# KM1M7CF16 register map
Vendor: Nuvoton Technology Corporation Japan; Series: KM1M7CF; File version: 1.0.3
CPU: CM7 r1p2, little endian, MPU, FPU, double-precision FPU, I-cache, D-cache, ITCM, DTCM, 4 interrupt priority bits
Registers are 32-bit, read-write, no defined reset value unless marked. A register's access mark holds for its fields unless they carry their own. Offsets are from the block's base; [hi:lo] are bit positions; {n}, {i} and the like mark numbered series.

## CAN — CAN FD Cotroller
Base 0x40110000
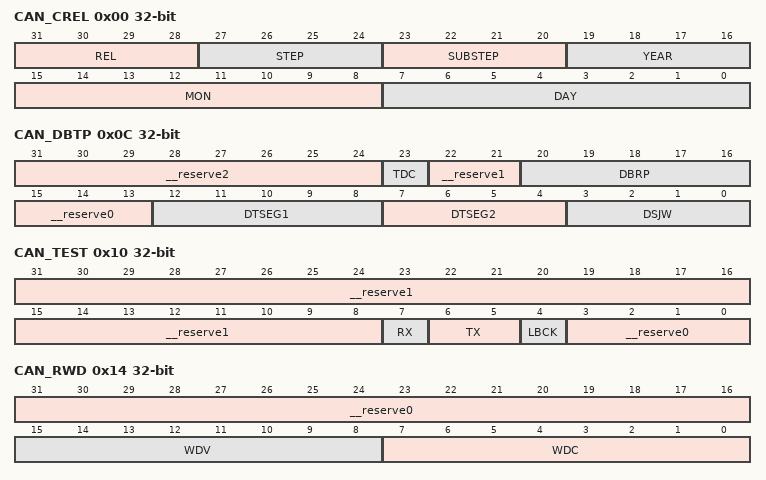
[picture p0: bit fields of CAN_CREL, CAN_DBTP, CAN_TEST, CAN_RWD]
0x00 CAN_CREL ro — CAN Core Release Register
  [31:28] REL — Core Release Version
  [27:24] STEP — Step of Core Release
  [23:20] SUBSTEP — Sub-step of Core Release
  [19:16] YEAR — Time Stamp Year
  [15:8] MON — Time Stamp Month
  [7:0] DAY — Time Stamp Day
0x0C CAN_DBTP access per field — CAN Data Bit Timing & Prescaler Register
  [31:24] __reserve2 ro — "0" is always read out.
  [23] TDC rw — Transmitter Delay Compensation
  [22:21] __reserve1 ro — "0" is always read out.
  [20:16] DBRP rw — Data Bit Rate Prescaler
  [15:13] __reserve0 ro — "0" is always read out.
  [12:8] DTSEG1 rw — Data time segment before sample point
  [7:4] DTSEG2 rw — Data time segment after sample point
  [3:0] DSJW rw — Data (Re)Synchronization Jump Width
0x10 CAN_TEST access per field
  [31:8] __reserve1 ro — "0" is always read out.
  [7] RX ro — Monitors the actual value of CRX pin
  [6:5] TX rw — Control of Transmit Pin CTX (*1)
  [4] LBCK rw — Loop Back Mode
  [3:0] __reserve0 ro — "0" is always read out.
0x14 CAN_RWD access per field — CAN RAM Watchdog Register
  [31:16] __reserve0 ro — "0" is always read out.
  [15:8] WDV ro — Watchdog Value
  [7:0] WDC rw — Watchdog Configuration
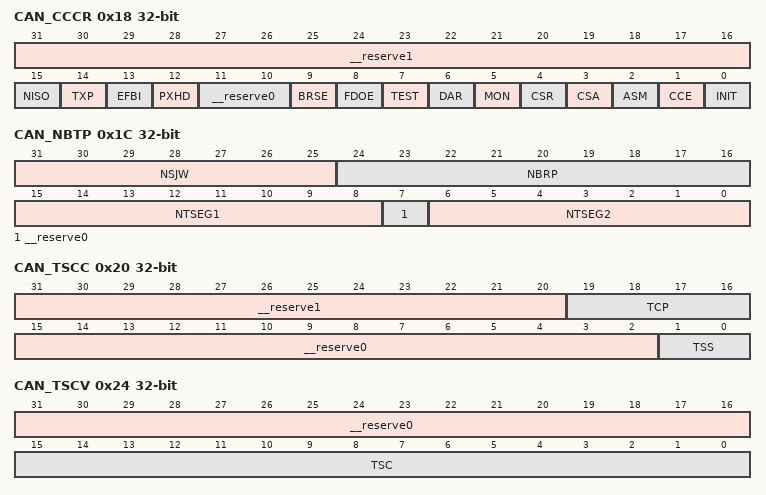
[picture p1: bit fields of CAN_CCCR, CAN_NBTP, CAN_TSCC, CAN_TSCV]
0x18 CAN_CCCR access per field — CAN CC Control Register
  [31:16] __reserve1 ro — "0" is always read out.
  [15] NISO rw — Non ISO Operation (*1)
  [14] TXP rw — Transmit Pause
  [13] EFBI rw — Edge Filtering during Bus Integration (*1)
  [12] PXHD rw — Protocol Exception Handling Disable (*1)
  [11:10] __reserve0 ro — "0" is always read out.
  [9] BRSE rw — Bit Rate Switch Enable (*1)
  [8] FDOE rw — CAN FD Operation Enable (*1)
  [7] TEST rw — Test Mode Enable (*2)
  [6] DAR rw — Disable Automatic Retransmission (*1)
  [5] MON rw — Bus Monitoring Mode (*2)
  [4] CSR rw — Clock Stop Request (*3)
  [3] CSA ro — Clock Stop Acknowledge
  [2] ASM rw — Restricted Operation Mode (*2)
  [1] CCE rw — Configuration Change Enable (*1) (*4)
  [0] INIT rw — Initialization (*5)
0x1C CAN_NBTP access per field — CAN Nominal Bit Timing & Prescaler Register
  [31:25] NSJW rw — Nominal (Re)Synchronization Jump Width
  [24:16] NBRP rw — Nominal Bit Rate Prescaler
  [15:8] NTSEG1 rw — Nominal Time segment (TSEG1) before sample point
  [7] __reserve0 ro — "0" is always read out.
  [6:0] NTSEG2 rw — Nominal Time segment (TSEG2) after sample point
0x20 CAN_TSCC access per field — CAN Timestamp Counter Configuration Register
  [31:20] __reserve1 ro — "0" is always read out.
  [19:16] TCP rw — Timestamp Counter Prescaler
  [15:2] __reserve0 ro — "0" is always read out.
  [1:0] TSS rw — Timestamp Selection
0x24 CAN_TSCV access per field — CAN Timestamp Counter Value Register
  [31:16] __reserve0 ro — "0" is always read out.
  [15:0] TSC rw — Timestamp Counter
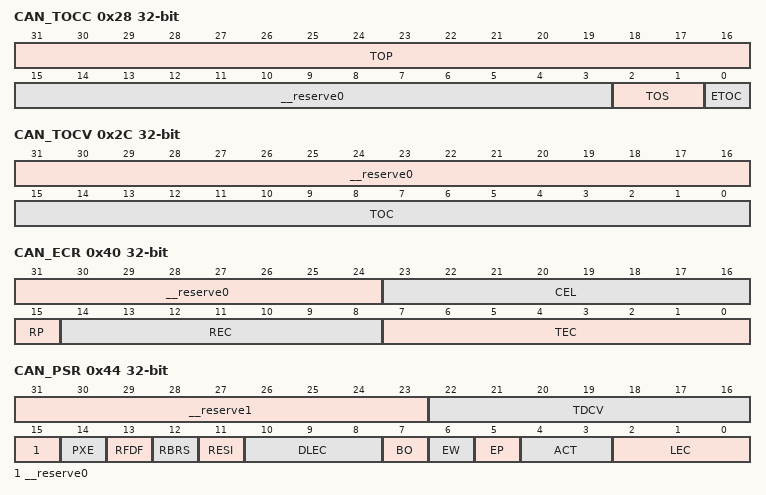
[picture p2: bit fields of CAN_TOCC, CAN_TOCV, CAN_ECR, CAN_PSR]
0x28 CAN_TOCC access per field — CAN Timeout Counter Configuration Register
  [31:16] TOP rw — Start value of the Timeout Counter (down-counter). Configures the Timeout Period.
  [15:3] __reserve0 ro — "0" is always read out.
  [2:1] TOS rw — Timeout Counter Operation mode Selection
  [0] ETOC rw — Enable Timeout Counter
0x2C CAN_TOCV access per field — CAN Timeout Counter Value Register
  [31:16] __reserve0 ro — "0" is always read out.
  [15:0] TOC rw — Timeout Counter Value
0x40 CAN_ECR ro — CAN Error Counter Register
  [31:24] __reserve0 — "0" is always read out.
  [23:16] CEL — CAN Error Logging (*1)
  [15] RP — Receive Error Passive
  [14:8] REC — Receive Error Counter
  [7:0] TEC — Transmit Error Counter
0x44 CAN_PSR ro — CAN Protocol Status Register
  [31:23] __reserve1 — "0" is always read out.
  [22:16] TDCV — Transmitter Delay Compensation Value (Position of the secondary sample point)
  [15] __reserve0 — "0" is always read out.
  [14] PXE — Protocol Exception Event (*1)
  [13] RFDF — Received a CAN FD Message (*1)
  [12] RBRS — BRS flag of last received CAN FD Message (*1)
  [11] RESI — ESI flag of last received CAN FD Message (*1)
  [10:8] DLEC — Data Phase Last Error Code
  [7] BO — Bus_Off Status
  [6] EW — Warning Status
  [5] EP — CAN Error Passive
  [4:3] ACT — Activity
  [2:0] LEC — Last error code to occur on the CAN bus.(*4) (*5)
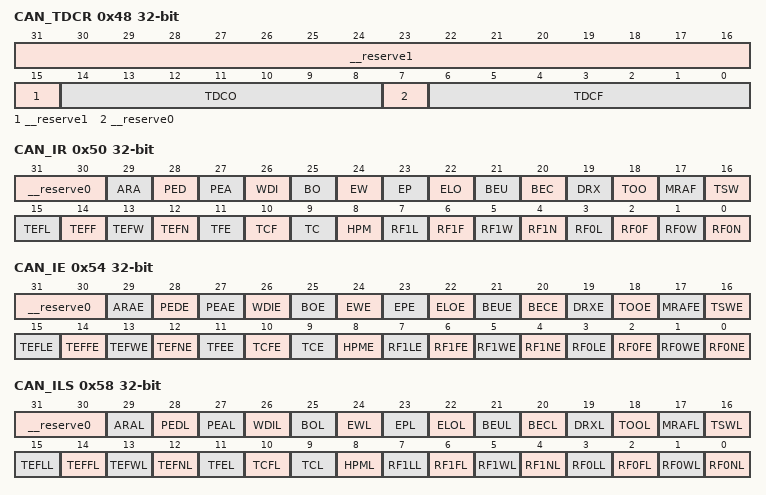
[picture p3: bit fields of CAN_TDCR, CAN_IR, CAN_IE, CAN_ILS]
0x48 CAN_TDCR access per field — CAN Transmitter Delay Compensation Register
  [31:15] __reserve1 ro — "0" is always read out.
  [14:8] TDCO rw — Transmitter Delay Compensation Offset
  [7] __reserve0 ro — "0" is always read out.
  [6:0] TDCF rw — Transmitter Delay Compensation Filter Window Length (*1)
0x50 CAN_IR access per field — CAN Interrupt Factor Register
  [31:30] __reserve0 ro — "0" is always read out.
  [29] ARA rw — Access to Reserved Address Interrupt Factor
  [28] PED rw — Protocol Error in Data Phase Interrupt Factor (Data Bit Time is used)
  [27] PEA rw — Protocol Error in Arbitration Phase Interrupt Factor (Nominal Bit Time is used)
  [26] WDI rw — Watchdog Interrupt Factor
  [25] BO rw — Bus_Off Status Interrupt Factor
  [24] EW rw — Warning Status Interrupt Factor
  [23] EP rw — Error Passive Interrupt Factor
  [22] ELO rw — Error Logging Overflow Interrupt Factor
  [21] BEU rw — Bit Error Uncorrected Interrupt Factor
  [20] BEC rw — Bit Error Corrected Interrupt Factor
  [19] DRX rw — Message stored to Dedicated Rx Buffer Interrupt Factor
  [18] TOO rw — Timeout Occurred Interrupt Factor
  [17] MRAF rw — Message RAM Access Failure Interrupt Factor
  [16] TSW rw — Timestamp Wraparound Interrupt Factor
  [15] TEFL rw — Tx Event FIFO Element Lost Interrupt Factor
  [14] TEFF rw — Tx Event FIFO Full Interrupt Factor
  [13] TEFW rw — Tx Event FIFO Watermark Reached Interrupt Factor
  [12] TEFN rw — Tx Event FIFO New Entry Interrupt Factor
  [11] TFE rw — Tx FIFO Empty Interrupt Factor
  [10] TCF rw — Transmission Cancellation Finished Interrupt Factor
  [9] TC rw — Transmission Completed Interrupt Factor
  [8] HPM rw — High Priority Message Interrupt Factor
  [7] RF1L rw — Rx FIFO 1 Message Lost Interrupt Factor
  [6] RF1F rw — Rx FIFO 1 Full Interrupt Factor
  [5] RF1W rw — Rx FIFO 1 Watermark Reached Interrupt Factor
  [4] RF1N rw — Rx FIFO 1 New Message Interrupt Factor
  [3] RF0L rw — Rx FIFO 0 Message Lost Interrupt Factor
  [2] RF0F rw — Rx FIFO 0 Full Interrupt Factor
  [1] RF0W rw — Rx FIFO 0 Watermark Reached Interrupt Factor
  [0] RF0N rw — Rx FIFO 0 New Message Interrupt Factor
0x54 CAN_IE access per field — CAN Interrupt Factor Enable Register
  [31:30] __reserve0 ro — "0" is always read out.
  [29] ARAE rw — Access to Reserved Address Interrupt Factor Enable
  [28] PEDE rw — Protocol Error in Data Phase Interrupt Factor Enable
  [27] PEAE rw — Protocol Error in Arbitration Phase Interrupt Factor Enable
  [26] WDIE rw — Watchdog Interrupt Factor Enable
  [25] BOE rw — Bus_Off Status Interrupt Factor Enable
  [24] EWE rw — Warning Status Interrupt Factor Enable
  [23] EPE rw — Error Passive Interrupt Factor Enable
  [22] ELOE rw — Error Logging Overflow Interrupt Factor Enable
  [21] BEUE rw — Bit Error Uncorrected Interrupt Factor Enable
  [20] BECE rw — Bit Error Corrected Interrupt Factor Enable
  [19] DRXE rw — Message stored to Dedicated Rx Buffer Interrupt Factor Enable
  [18] TOOE rw — Timeout Occurred Interrupt Factor Enable
  [17] MRAFE rw — Message RAM Access Failure Interrupt Factor Enable
  [16] TSWE rw — Timestamp Wraparound Interrupt Factor Enable
  [15] TEFLE rw — Tx Event FIFO Event Lost Interrupt Factor Enable
  [14] TEFFE rw — Tx Event FIFO Full Interrupt Factor Enable
  [13] TEFWE rw — Tx Event FIFO Watermark Reached Interrupt Factor Enable
  [12] TEFNE rw — Tx Event FIFO New Entry Interrupt Factor Enable
  [11] TFEE rw — Tx FIFO Empty Interrupt Factor Enable
  [10] TCFE rw — Transmission Cancellation Finished Interrupt Factor Enable
  [9] TCE rw — Transmission Completed Interrupt Factor Enable
  [8] HPME rw — High Priority Message Interrupt Factor Enable
  [7] RF1LE rw — Rx FIFO 1 Message Lost Interrupt Factor Enable
  [6] RF1FE rw — Rx FIFO 1 Full Interrupt Factor Enable
  [5] RF1WE rw — Rx FIFO 1 Watermark Reached Interrupt Factor Enable
  [4] RF1NE rw — Rx FIFO 1 New Message Interrupt Factor Enable
  [3] RF0LE rw — Rx FIFO 0 Message Lost Interrupt Factor Enable
  [2] RF0FE rw — Rx FIFO 0 Full Interrupt Factor Enable
  [1] RF0WE rw — Rx FIFO 0 Watermark Reached Interrupt Factor Enable
  [0] RF0NE rw — Rx FIFO 0 New Message Interrupt Factor Enable
0x58 CAN_ILS access per field — CAN Interrupt Line Select Register
  [31:30] __reserve0 ro — "0" is always read out.
  [29] ARAL rw — Access to Reserved Address Line
  [28] PEDL rw — Protocol Error in Data Phase Line
  [27] PEAL rw — Protocol Error in Arbitration Phase Line
  [26] WDIL rw — Watchdog Interrupt Line
  [25] BOL rw — Bus_Off Status Interrupt Line
  [24] EWL rw — Warning Status Interrupt Line
  [23] EPL rw — Error Passive Interrupt Line
  [22] ELOL rw — Error Logging Overflow Interrupt Line
  [21] BEUL rw — Bit Error Uncorrected Interrupt Line
  [20] BECL rw — Bit Error Corrected Interrupt Line
  [19] DRXL rw — Message stored to Dedicated Rx Buffer Interrupt Line
  [18] TOOL rw — Timeout Occurred Interrupt Line
  [17] MRAFL rw — Message RAM Access Failure Interrupt Line
  [16] TSWL rw — Timestamp Wraparound Interrupt Line
  [15] TEFLL rw — Tx Event FIFO Event Lost Interrupt Line
  [14] TEFFL rw — Tx Event FIFO Full Interrupt Line
  [13] TEFWL rw — Tx Event FIFO Watermark Reached Interrupt Line
  [12] TEFNL rw — Tx Event FIFO New Entry Interrupt Line
  [11] TFEL rw — Tx FIFO Empty Interrupt Line
  [10] TCFL rw — Transmission Cancellation Finished Interrupt Line
  [9] TCL rw — Transmission Completed Interrupt Line
  [8] HPML rw — High Priority Message Interrupt Line
  [7] RF1LL rw — Rx FIFO 1 Message Lost Interrupt Line
  [6] RF1FL rw — Rx FIFO 1 Full Interrupt Line
  [5] RF1WL rw — Rx FIFO 1 Watermark Reached Interrupt Line
  [4] RF1NL rw — Rx FIFO 1 New Message Interrupt Line
  [3] RF0LL rw — Rx FIFO 0 Message Lost Interrupt Line
  [2] RF0FL rw — Rx FIFO 0 Full Interrupt Line
  [1] RF0WL rw — Rx FIFO 0 Watermark Reached Interrupt Line
  [0] RF0NL rw — Rx FIFO 0 New Message Interrupt Line
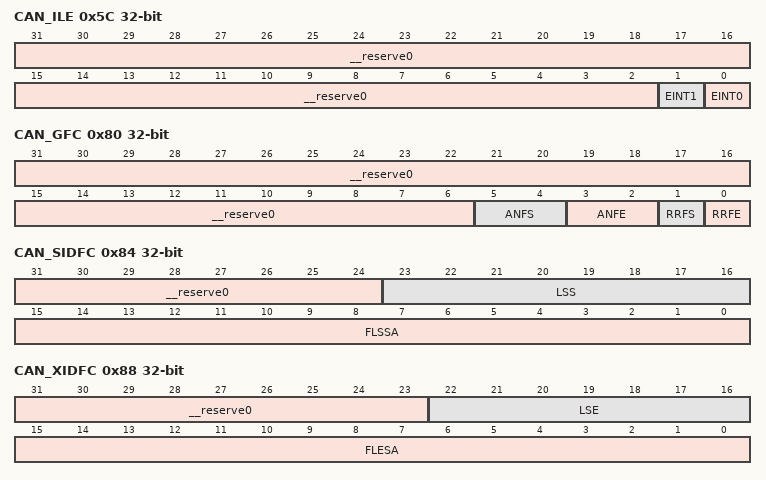
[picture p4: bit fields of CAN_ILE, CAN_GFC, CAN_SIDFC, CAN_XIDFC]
0x5C CAN_ILE access per field — CAN Interrupt Line Enable Register
  [31:2] __reserve0 ro — "0" is always read out.
  [1] EINT1 rw — Enable CAN-1 Interrupt
  [0] EINT0 rw — Enable CAN-0 Interrupt
0x80 CAN_GFC access per field — CAN Global Filter Configuration Register
  [31:6] __reserve0 ro — "0" is always read out.
  [5:4] ANFS rw — Accept Non-matching Frames Standard Message ID (11-bit)
  [3:2] ANFE rw — Accept Non-matching Frames Extended Message ID (29-bit)
  [1] RRFS rw — Reject Remote Frames Standard Message ID (11-bit)
  [0] RRFE rw — Reject Remote Frames Extended Message ID (29-bit)
0x84 CAN_SIDFC access per field — CAN Standard ID Filter Configuration Register
  [31:24] __reserve0 ro — "0" is always read out.
  [23:16] LSS rw — List Size Standard Message ID (11-bit)
  [15:0] FLSSA rw — Start address of Standard Message ID (11-bit) filter list (*1)
0x88 CAN_XIDFC access per field — CAN Extended ID Filter Configuration Register
  [31:23] __reserve0 ro — "0" is always read out.
  [22:16] LSE rw — List Size Extended Message ID (29-bit)
  [15:0] FLESA rw — Start address of Extended Message ID (29-bit) filter list (*1)
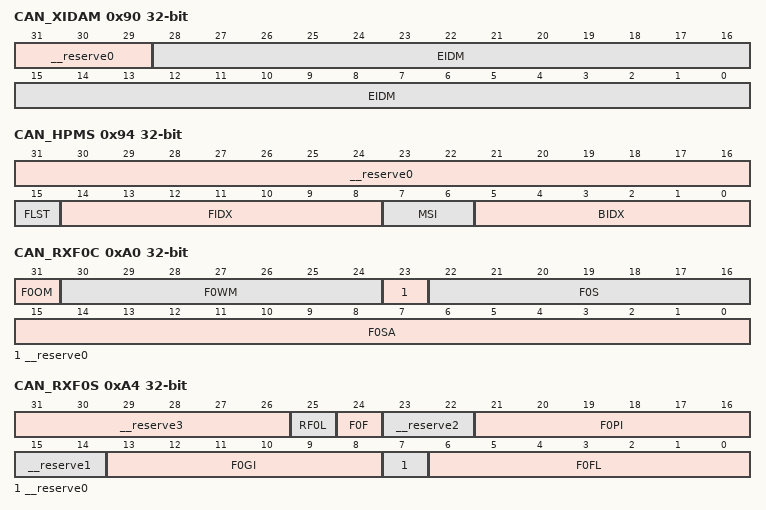
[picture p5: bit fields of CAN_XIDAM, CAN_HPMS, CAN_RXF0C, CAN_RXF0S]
0x90 CAN_XIDAM access per field — CAN Extended ID AND Mask Register
  [31:29] __reserve0 ro — "0" is always read out.
  [28:0] EIDM rw — Extended Message ID Mask (*1)
0x94 CAN_HPMS ro — CAN High Priority Message Status Register
  [31:16] __reserve0 — "0" is always read out.
  [15] FLST — Filter List
  [14:8] FIDX — Filter Index
  [7:6] MSI — Message Storage Indicator
  [5:0] BIDX — Buffer Index
0x98 CAN_NDAT1 — CAN New Data 1 Register
  [31:0] ND1 — New Data flags of Rx Buffers 0 to 31 (bp0 to 31)
0x9C CAN_NDAT2 — CAN New Data 2 Register
  [31:0] ND2 — New Data flags of Rx Buffers 32 to 63 (bp0 to 31)
0xA0 CAN_RXF0C access per field — CAN Rx FIFO 0 Configuration Register
  [31] F0OM rw — FIFO 0 Operation Mode
  [30:24] F0WM rw — Rx FIFO 0 Watermark
  [23] __reserve0 ro — "0" is always read out.
  [22:16] F0S rw — Rx FIFO 0 Size
  [15:0] F0SA rw — Start address of Rx FIFO 0 in Message RAM (*1)
0xA4 CAN_RXF0S ro — CAN Rx FIFO 0 Status Register
  [31:26] __reserve3 — "0" is always read out.
  [25] RF0L — Rx FIFO 0 Message Lost (*1) (*2)
  [24] F0F — Rx FIFO 0 Full
  [23:22] __reserve2 — "0" is always read out.
  [21:16] F0PI — Rx FIFO 0 Put Index
  [15:14] __reserve1 — "0" is always read out.
  [13:8] F0GI — Rx FIFO 0 Get Index
  [7] __reserve0 — "0" is always read out.
  [6:0] F0FL — Rx FIFO 0 Fill Level
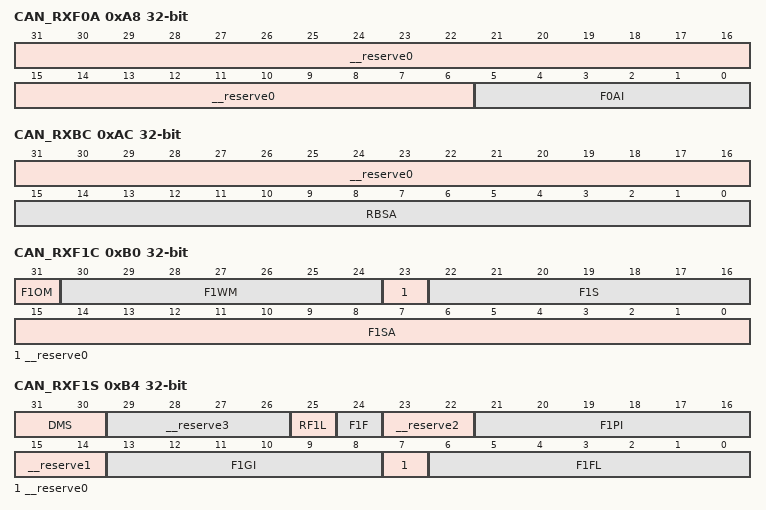
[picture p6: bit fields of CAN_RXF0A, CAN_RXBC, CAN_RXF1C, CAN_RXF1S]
0xA8 CAN_RXF0A access per field — CAN Rx FIFO 0 Acknowledge Register
  [31:6] __reserve0 ro — "0" is always read out.
  [5:0] F0AI rw — Rx FIFO 0 Acknowledge Index (*1)
0xAC CAN_RXBC access per field — CAN Rx Buffer Configuration Register
  [31:16] __reserve0 ro — "0" is always read out.
  [15:0] RBSA rw — Start address of Rx Buffers in Message RAM (*1) (*2)
0xB0 CAN_RXF1C access per field — CAN Rx FIFO 1 Configuration Register
  [31] F1OM rw — Rx FIFO 1 Operation Mode
  [30:24] F1WM rw — Rx FIFO 1 Watermark
  [23] __reserve0 ro — "0" is always read out.
  [22:16] F1S rw — Rx FIFO 1 Size
  [15:0] F1SA rw — Start address of Rx FIFO 1 in Message RAM (*1)
0xB4 CAN_RXF1S ro — CAN Rx FIFO 1 Status Register
  [31:30] DMS — Debug Message Status
  [29:26] __reserve3 — "0" is always read out.
  [25] RF1L — Rx FIFO 1 Message Lost (*1) (*2)
  [24] F1F — Rx FIFO 1 Full
  [23:22] __reserve2 — "0" is always read out.
  [21:16] F1PI — Rx FIFO 1 Put Index
  [15:14] __reserve1 — "0" is always read out.
  [13:8] F1GI — Rx FIFO 1 Get Index
  [7] __reserve0 — "0" is always read out.
  [6:0] F1FL — Rx FIFO 1 Fill Level
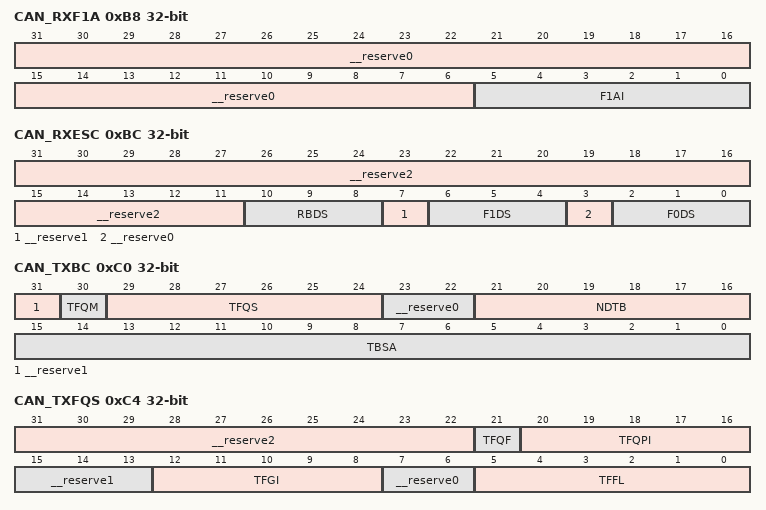
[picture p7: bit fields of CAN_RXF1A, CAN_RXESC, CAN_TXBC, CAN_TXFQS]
0xB8 CAN_RXF1A access per field — CAN Rx FIFO 1 Acknowledge Register
  [31:6] __reserve0 ro — "0" is always read out.
  [5:0] F1AI rw — Rx FIFO 1 Acknowledge Index
0xBC CAN_RXESC access per field — CAN Rx Buffer/ FIFO Element Size Configuration Register
  [31:11] __reserve2 ro — "0" is always read out.
  [10:8] RBDS rw — Rx Buffer Data Field Size (*1)
  [7] __reserve1 ro — "0" is always read out.
  [6:4] F1DS rw — Rx FIFO 1 Data Field Size (*1)
  [3] __reserve0 ro — "0" is always read out.
  [2:0] F0DS rw — Rx FIFO 0 Data Field Size (*1)
0xC0 CAN_TXBC access per field — CAN Tx Buffer Configuration Register
  [31] __reserve1 ro — "0" is always read out.
  [30] TFQM rw — Tx FIFO/Queue Mode
  [29:24] TFQS rw — Tx FIFO/Queue Size (*1)
  [23:22] __reserve0 ro — "0" is always read out.
  [21:16] NDTB rw — Number of Dedicated Tx Buffers (*1)
  [15:0] TBSA rw — Start address of Tx Buffers in Message RAM (*2) (*3)
0xC4 CAN_TXFQS ro — CAN Tx FIFO/Queue Status Register
  [31:22] __reserve2 — "0" is always read out.
  [21] TFQF — Tx FIFO/Queue Full
  [20:16] TFQPI — Tx FIFO/Queue Put Index
  [15:13] __reserve1 — "0" is always read out.
  [12:8] TFGI — Tx FIFO Get Index (*1)
  [7:6] __reserve0 — "0" is always read out.
  [5:0] TFFL — Tx FIFO Free Level
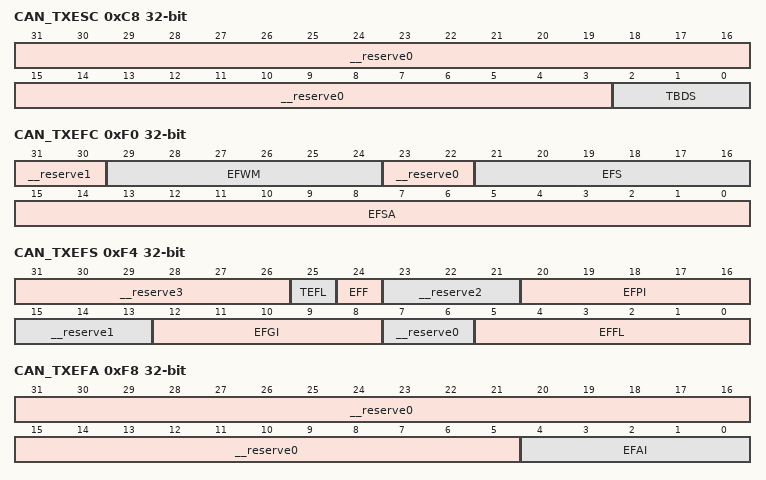
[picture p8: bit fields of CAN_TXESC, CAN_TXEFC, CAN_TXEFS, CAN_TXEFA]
0xC8 CAN_TXESC access per field — CAN Tx Buffer Element Size Configuration Register
  [31:3] __reserve0 ro — "0" is always read out.
  [2:0] TBDS rw — Tx Buffer Data Field Size (*1)
0xCC CAN_TXBRP ro — CAN Tx Buffer Request Pending Register
  [31:0] TRP — Transmission Request Pending
0xD0 CAN_TXBAR — CAN Tx Buffer Add Request Register
  [31:0] AR — Add Request
0xD4 CAN_TXBCR — CAN Tx Buffer Cancellation Request Register
  [31:0] CR — Cancellation Request
0xD8 CAN_TXBTO ro — CAN Tx Buffer Transmission Occurred Register
  [31:0] TO — Transmission Occurred
0xDC CAN_TXBCF ro — CAN Tx Buffer Cancellation Finished Register
  [31:0] CF — Transmit Buffer Cancellation Finished
0xE0 CAN_TXBTIE — CAN Tx Buffer Transmission Interrupt Enable Register
  [31:0] TIE — Tx Buffer Transmission Interrupt Enable
0xE4 CAN_TXBCIE — CAN Tx Buffer Cancellation Finished Interrupt Enable Register
  [31:0] CFIE — Tx Buffer Cancellation Finished Interrupt Enable
0xF0 CAN_TXEFC access per field — CAN Tx Event FIFO Configuration Register
  [31:30] __reserve1 ro — "0" is always read out.
  [29:24] EFWM rw — Event FIFO Watermark
  [23:22] __reserve0 ro — "0" is always read out.
  [21:16] EFS rw — Event FIFO Size
  [15:0] EFSA rw — Start address of Tx Event FIFO in Message RAM (*1)
0xF4 CAN_TXEFS ro — CAN Tx Event FIFO Status Register
  [31:26] __reserve3 — "0" is always read out.
  [25] TEFL — Tx Event FIFO Element Lost (*1)
  [24] EFF — Event FIFO Full
  [23:21] __reserve2 — "0" is always read out.
  [20:16] EFPI — Event FIFO Put Index
  [15:13] __reserve1 — "0" is always read out.
  [12:8] EFGI — Event FIFO Get Index
  [7:6] __reserve0 — "0" is always read out.
  [5:0] EFFL — Event FIFO Fill Level
0xF8 CAN_TXEFA access per field — CAN Tx Event FIFO Acknowledge Register
  [31:5] __reserve0 ro — "0" is always read out.
  [4:0] EFAI rw — Event FIFO Acknowledge Index
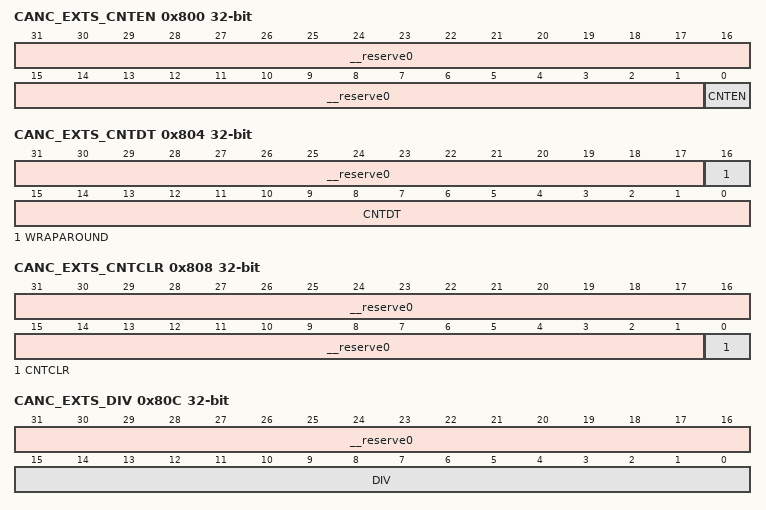
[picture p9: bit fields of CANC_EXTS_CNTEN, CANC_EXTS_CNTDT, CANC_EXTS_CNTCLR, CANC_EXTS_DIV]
0x800 CANC_EXTS_CNTEN access per field — External Timestamp Counter Control Register
  [31:1] __reserve0 ro — "0" is always read out.
  [0] CNTEN rw — Operation control of External timestamp counter
0x804 CANC_EXTS_CNTDT ro — External Timestamp Counter Display Register
  [31:17] __reserve0 — "0" is always read out.
  [16] WRAPAROUND — Status of External timestamp counter
  [15:0] CNTDT — Display the value of External timestamp counter.
0x808 CANC_EXTS_CNTCLR access per field — External Timestamp Counter Clear Register
  [31:1] __reserve0 ro — "0" is always read out.
  [0] CNTCLR wo — Clear the value of External timestamp counter (*1)
0x80C CANC_EXTS_DIV access per field — External Timestamp Counter Dividing Register
  [31:16] __reserve0 ro — "0" is always read out.
  [15:0] DIV rw — Clock dividing ratio of External timestamp counter (*1)
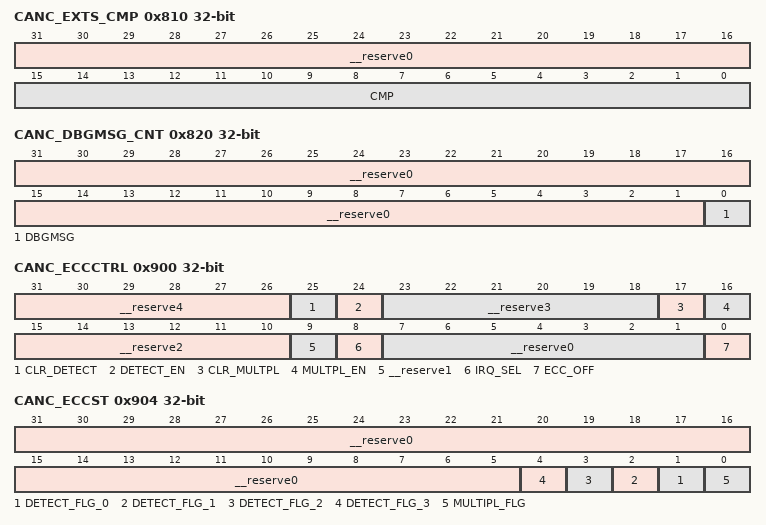
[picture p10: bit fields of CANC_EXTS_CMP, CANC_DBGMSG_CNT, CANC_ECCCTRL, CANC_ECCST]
0x810 CANC_EXTS_CMP access per field — External Timestamp Counter Compare Clear Register
  [31:16] __reserve0 ro — "0" is always read out.
  [15:0] CMP rw — Set the compare value of External timestamp counter.
0x820 CANC_DBGMSG_CNT access per field — Debug Message Control Register
  [31:1] __reserve0 ro — "0" is always read out.
  [0] DBGMSG rw — Debug Message Request of CAN
0x900 CANC_ECCCTRL access per field — ECC Function Setting Register
  [31:26] __reserve4 ro — "0" is always read out.
  [25] CLR_DETECT rw — Clear each status information detected when ECC error (1 bit or more) occurs (*1)
  [24] DETECT_EN rw — Enable each status information detection function when ECC error (1 bit or more) occurs
  [23:18] __reserve3 ro — "0" is always read out.
  [17] CLR_MULTPL rw — Clear each status information detected when ECC error (2 bits) occurs (*1)
  [16] MULTPL_EN rw — Enable each status information detection function when ECC error (2 bits) occurs
  [15:10] __reserve2 ro — "0" is always read out.
  [9] __reserve1 rw — This bit must be set to "0".
  [8] IRQ_SEL rw — Interrupt factor selection when ECC error occurs
  [7:1] __reserve0 ro — "0" is always read out.
  [0] ECC_OFF rw — ECC function ON/OFF
0x904 CANC_ECCST ro — ECC Error Detection Flag Register
  [31:5] __reserve0 — "0" is always read out.
  [n+1] DETECT_FLG_{n} (n=0..3) — ECC error (1 bit or more) occurrence (*1)
  [0] MULTIPL_FLG — ECC error (2 bits) occurrence detection (*2)
0x90C CANC_ECCRAM_DBG — ECCRAM Debug Register
  [31:0] ECCRAM_DBG_KEY — Switching access route to ECC part of message RAM
0x910 CANC_ERR_MULTPL_ADDR ro — ECC Error (2 bits) Detection Address Register
  [31:0] ERR_MULTPL_ADDR — Detect and display address at the time of ECC error (2 bits) occurrence.
0x914 CANC_ERR_MULTPL_DATA ro — ECC Error (2 bits) Detection Data Register
  [31:0] ERR_MULTPL_DATA — Detect and display data at the time of ECC error (2 bits) occurrence.
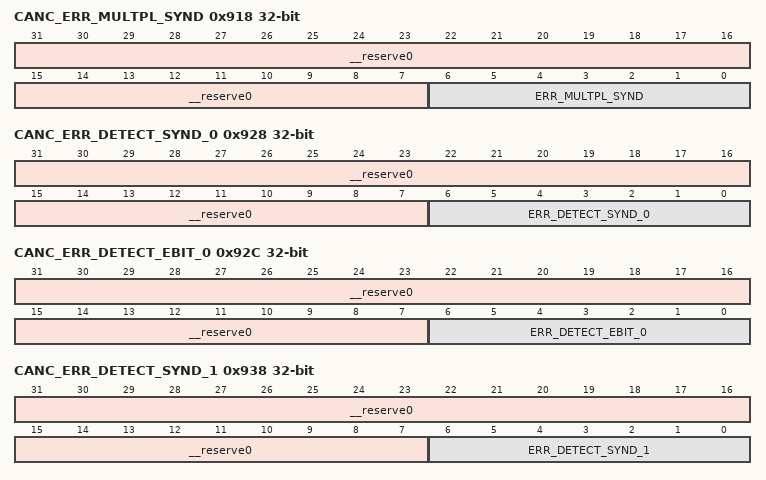
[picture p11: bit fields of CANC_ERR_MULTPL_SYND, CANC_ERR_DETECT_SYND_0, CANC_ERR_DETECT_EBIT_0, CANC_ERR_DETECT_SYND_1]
0x918 CANC_ERR_MULTPL_SYND ro — ECC Error (2 bits) Detection ECC Data Register
  [31:7] __reserve0 — "0" is always read out.
  [6:0] ERR_MULTPL_SYND — Detect and display ECC data at the time of ECC error (2 bits) occurrence.
{0x920+0x10*i} CANC_ERR_DETECT_ADDR_{i} ro (i=0..3) — ECC Error (1 bit or more) Detection Address Register {i}
  [31:0] ERR_DETECT_ADDR_{i} — Detect and display address at the time of ECC error (1 bit or more) occurrence.
0x924 CANC_ERR_DETECT_DATA_0 ro — ECC Error (1 bit or more) Detection Data Register 0
  [31:0] ERR_DETECT_DATA_0 — Detect data at the time of ECC error (1 bit or more) occurrence, and display the value before correction.
0x928 CANC_ERR_DETECT_SYND_0 ro — ECC Error (1 bit or more) Detection ECC Data Register 0
  [31:7] __reserve0 — "0" is always read out.
  [6:0] ERR_DETECT_SYND_0 — Detect ECC data at the time of ECC error (1 bit or more) occurrence, and display the value before correction.
0x92C CANC_ERR_DETECT_EBIT_0 ro — ECC Error (1 bit or more) Target Bit Register 0
  [31:7] __reserve0 — "0" is always read out.
  [6:0] ERR_DETECT_EBIT_0 — Detect and display the target bit at the time of ECC error (1 bit or more) occurrence.
0x934 CANC_ERR_DETECT_DATA_1 ro — ECC Error (1 bit or more) Detection Data Register 1
  [31:0] ERR_DETECT_DATA_1 — Detect data at the time of ECC error (1 bit or more) occurrence, and display the value before correction.
0x938 CANC_ERR_DETECT_SYND_1 ro — ECC Error (1 bit or more) Detection ECC Data Register 1
  [31:7] __reserve0 — "0" is always read out.
  [6:0] ERR_DETECT_SYND_1 — Detect ECC data at the time of ECC error (1 bit or more) occurrence, and display the value before correction.
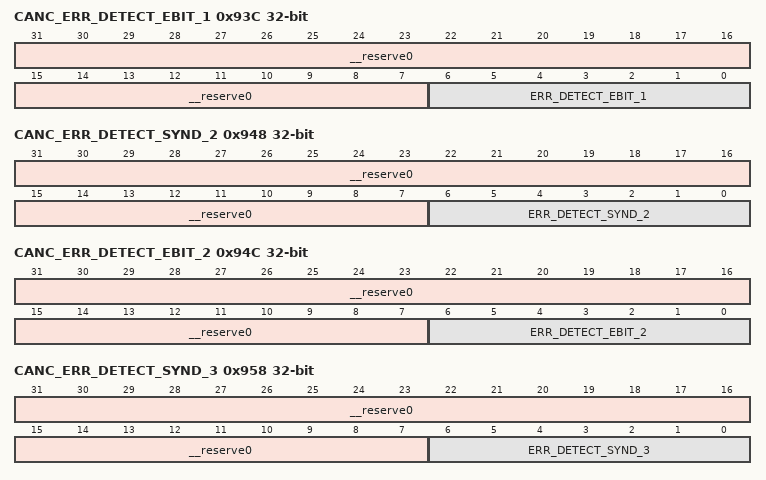
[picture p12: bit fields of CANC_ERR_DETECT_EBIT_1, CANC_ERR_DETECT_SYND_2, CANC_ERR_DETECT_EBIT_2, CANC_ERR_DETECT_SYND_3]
0x93C CANC_ERR_DETECT_EBIT_1 ro — ECC Error (1 bit or more) Target Bit Register 1
  [31:7] __reserve0 — "0" is always read out.
  [6:0] ERR_DETECT_EBIT_1 — Detect and display the target bit at the time of ECC error (1 bit or more) occurrence. (2nd stage FIFO)
0x944 CANC_ERR_DETECT_DATA_2 ro — ECC Error (1 bit or more) Detection Data Register 2
  [31:0] ERR_DETECT_DATA_2 — Detect data at the time of ECC error (1bit or more) occurrence, and display the value before correction.
0x948 CANC_ERR_DETECT_SYND_2 ro — ECC Error (1 bit or more) Detection ECC Data Register 2
  [31:7] __reserve0 — "0" is always read out.
  [6:0] ERR_DETECT_SYND_2 — Detect ECC data at the time of ECC error (1bit or more) occurrence, and display the value before correction.
0x94C CANC_ERR_DETECT_EBIT_2 ro — ECC Error (1 bit or more) Target Bit Register 2
  [31:7] __reserve0 — "0" is always read out.
  [6:0] ERR_DETECT_EBIT_2 — Detect and display the target bit at the time of ECC error (1 bit or more) occurrence. (3rd stage FIFO)
0x954 CANC_ERR_DETECT_DATA_3 ro — ECC Error (1 bit or more) Detection Data Register 3
  [31:0] ERR_DETECT_DATA_3 — Detect data at the time of ECC error (1bit or more) occurrence, and display the value before correction.
0x958 CANC_ERR_DETECT_SYND_3 ro — ECC Error (1 bit or more) Detection ECC Data Register 3
  [31:7] __reserve0 — "0" is always read out.
  [6:0] ERR_DETECT_SYND_3 — Detect ECC data at the time of ECC error (1bit or more) occurrence, and display the value before correction.
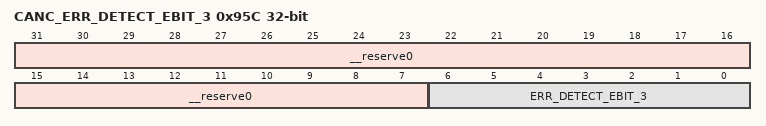
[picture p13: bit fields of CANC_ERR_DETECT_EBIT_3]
0x95C CANC_ERR_DETECT_EBIT_3 ro — ECC Error (1 bit or more) Target Bit Register 3
  [31:7] __reserve0 — "0" is always read out.
  [6:0] ERR_DETECT_EBIT_3 — Detect and display the target bit at the time of ECC error (1 bit or more) occurrence. (4th stage FIFO)
